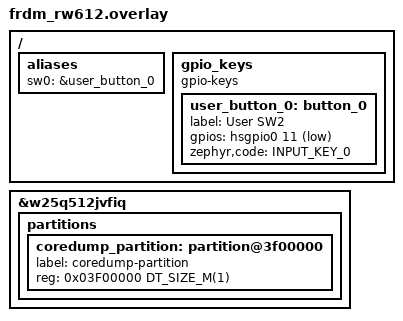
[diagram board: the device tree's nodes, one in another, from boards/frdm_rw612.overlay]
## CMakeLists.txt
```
# SPDX-License-Identifier: Apache-2.0

cmake_minimum_required(VERSION 3.20.0)

if (EXISTS "${CMAKE_CURRENT_SOURCE_DIR}/credentials.conf")
    list(APPEND EXTRA_CONF_FILE "${CMAKE_CURRENT_SOURCE_DIR}/credentials.conf")
endif()


find_package(Zephyr REQUIRED HINTS $ENV{ZEPHYR_BASE})
project(coredumps-eth)

target_sources(app PRIVATE
        src/main.c
)
```

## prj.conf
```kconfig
CONFIG_SPOTFLOW=y
CONFIG_SPOTFLOW_COREDUMPS=y
#CONFIG_SPOTFLOW_GENERATE_BUILD_ID=n

#CONFIG_NET_ARP=y
CONFIG_NET_SHELL=y
#configure what should be included in the coredump
#CONFIG_DEBUG_COREDUMP_MEMORY_DUMP_MIN=y
CONFIG_DEBUG_COREDUMP_THREADS_METADATA=y
CONFIG_DEBUG_COREDUMP_MEMORY_DUMP_THREADS=y

#configure spotflow internal logging levels
CONFIG_SPOTFLOW_MODULE_DEFAULT_LOG_LEVEL=4

# configure if the function names should be included in the logs
CONFIG_LOG_FUNC_NAME_PREFIX_INF=y
CONFIG_LOG_FUNC_NAME_PREFIX_WRN=y
CONFIG_LOG_FUNC_NAME_PREFIX_ERR=y

CONFIG_GPIO=y

#logging
CONFIG_PRINTK=y
CONFIG_LOG=y

# net
CONFIG_NETWORKING=y
CONFIG_NET_MGMT=y
CONFIG_NET_MGMT_EVENT=y
CONFIG_NET_MGMT_EVENT_INFO=y
CONFIG_NET_CONFIG_AUTO_INIT=n
CONFIG_NET_CONNECTION_MANAGER=y
CONFIG_NET_DHCPV4=y
CONFIG_NET_IPV4=y
CONFIG_NET_IPV6=n
CONFIG_NET_TCP=y
CONFIG_NET_UDP=y
```

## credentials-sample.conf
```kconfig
# Copy this file to credentials.conf and fill in the values
CONFIG_SPOTFLOW_DEVICE_ID=""
CONFIG_SPOTFLOW_INGEST_KEY=""
```

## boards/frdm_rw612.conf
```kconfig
CONFIG_WIFI_NXP=n
CONFIG_ETH_DRIVER=y
CONFIG_NET_L2_ETHERNET_MGMT=y

#fix buffer size for RW612 on Zephyr 4.1.0
CONFIG_NET_BUF_DATA_SIZE=1744

CONFIG_NXP_WIFI_SOFTAP_SUPPORT=n
```

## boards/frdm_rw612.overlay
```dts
/*GPIO not available in 4.1.0, adding based on commit
https://github.com/zephyrproject-rtos/zephyr/commit/2df6b7fd2dea95105b3598c41fecbd7089fab080*/
#include <zephyr/dt-bindings/input/input-event-codes.h>
/ {
	aliases {
		/* make an alias so we can refer to “sw0” in code */
		sw0 = &user_button_0;
	};

	gpio_keys {
		compatible = "gpio-keys";
		user_button_0: button_0 {
			label = "User SW2";
			gpios = <&hsgpio0 11 (GPIO_ACTIVE_LOW | GPIO_PULL_UP)>;
			zephyr,code = <INPUT_KEY_0>;
			status = "okay";
		};
	};
};

/* external flash chip - winbond - to more information
	  zephyr\boards\nxp\frdm_rw612\frdm_rw612_common.dtsi*/
&w25q512jvfiq {
	partitions {
		coredump_partition: partition@3f00000 {
			label = "coredump-partition";
			reg   = <0x03F00000 DT_SIZE_M(1)>; /* last 1MB of 64 MB flash */
		};
	};
};
```

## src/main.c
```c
#include <zephyr/kernel.h>
#include <zephyr/logging/log.h>

#include "zephyr/debug/coredump.h"

#include "zephyr/drivers/gpio.h"
#include "zephyr/net/net_if.h"

#include <zephyr/device.h>

LOG_MODULE_REGISTER(MAIN, LOG_LEVEL_INF);

#define SW0_NODE DT_ALIAS(sw0)
#if !DT_NODE_HAS_STATUS_OKAY(SW0_NODE)
#error "Unsupported board: sw2 devicetree alias is not defined"
#endif

static const struct gpio_dt_spec button = GPIO_DT_SPEC_GET_OR(SW0_NODE, gpios, { 0 });
static struct gpio_callback button_cb_data;

static int prepare_button();

static void handler(struct net_mgmt_event_callback *cb,
		    uint32_t mgmt_event, struct net_if *iface)
{
	LOG_INF("Network event received: %u", mgmt_event);
	if (mgmt_event == NET_EVENT_IF_UP) {
		LOG_INF("Interface is up -> starting DHCPv4");
		net_dhcpv4_start(iface);
	}
}

int main(void)
{
	LOG_INF("Starting Spotflow logging example");
	LOG_INF("Press button to oops the device. "
		"Coredump will be created and sent to Spotflow on reboot.");
	int ret;
	ret = prepare_button();
	if (ret != 0) {
		LOG_ERR("Failed to prepare button, exiting");
		return ret;
	}

	/*start the dhcp on ethernet interface - not started by default*/
	struct net_if* iface = net_if_get_default();
	if (net_if_is_up(iface)) {
		net_dhcpv4_start(iface);
	}else {
		LOG_ERR("Default network interface is not up");
	}
	int i = 0;
	while (true) {
		LOG_INF("Hello from Zephyr to Spotflow: %d", i++);
		k_sleep(K_SECONDS(2));
	}
}

static void button_pressed(const struct device* dev, struct gpio_callback* cb, uint32_t pins)
{
	LOG_INF("Button pressed. Going to oops.");
	k_oops();
}

static int prepare_button()
{
	int ret;
	if (!gpio_is_ready_dt(&button)) {
		LOG_ERR("Error: button device %s is not ready", button.port->name);
		return -EINVAL;
	}

	ret = gpio_pin_configure_dt(&button, GPIO_INPUT);
	if (ret != 0) {
		LOG_ERR("Error %d: failed to configure %s pin %d", ret, button.port->name,
			button.pin);
		return ret;
	}

	ret = gpio_pin_interrupt_configure_dt(&button, GPIO_INT_EDGE_TO_ACTIVE);
	if (ret != 0) {
		LOG_ERR("Error %d: failed to configure interrupt on %s pin %d", ret,
			button.port->name, button.pin);
		return ret;
	}

	gpio_init_callback(&button_cb_data, button_pressed, BIT(button.pin));
	gpio_add_callback(button.port, &button_cb_data);

	LOG_DBG("Set up button at %s pin %d", button.port->name, button.pin);
	return 0;
}
```
